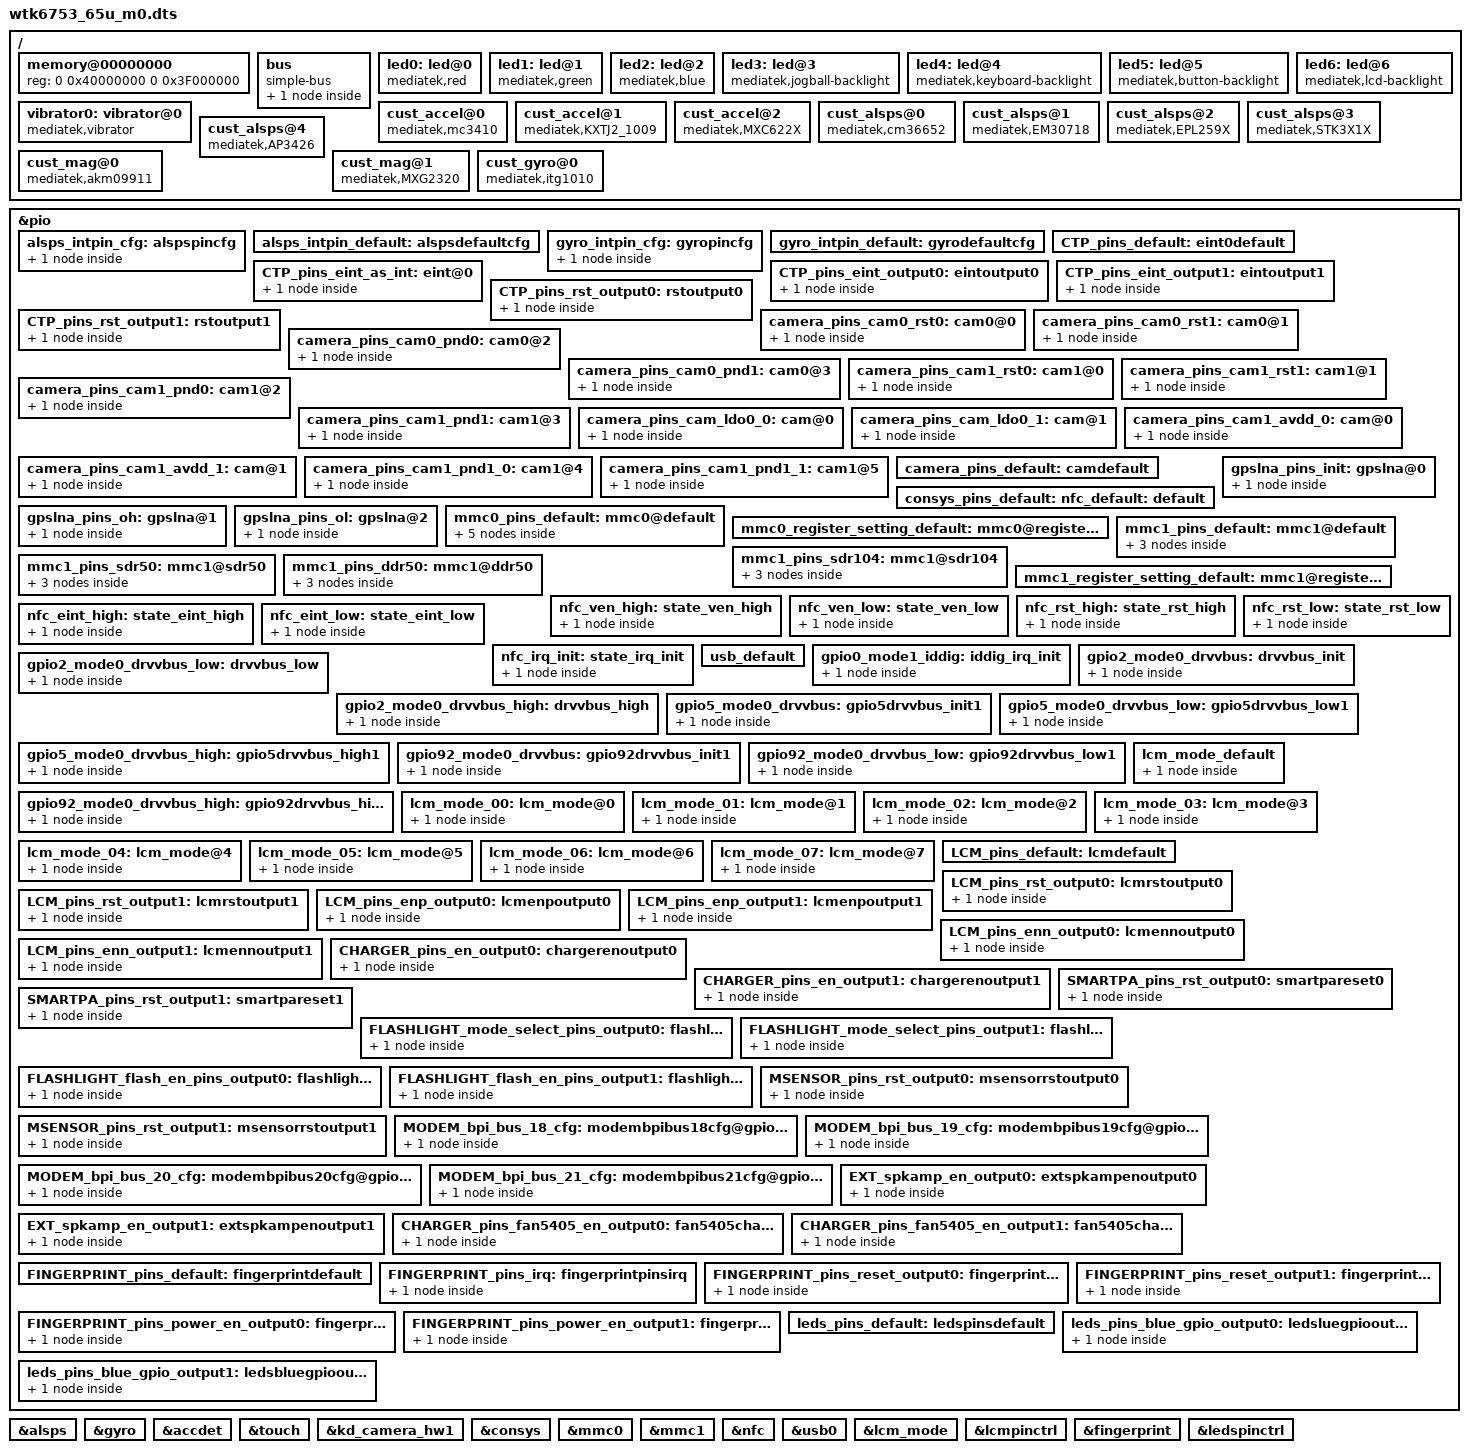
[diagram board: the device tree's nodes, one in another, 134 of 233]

/dts-v1/;

#include "mt6753.dtsi"
#include <dt-bindings/lcm/r63417_fhd_dsi_cmd_truly_nt50358.dtsi>

/ {
memory@00000000 {
		device_type = "memory";
		reg = <0 0x40000000 0 0x3F000000>;
	};

	bus {
		compatible = "simple-bus";
		#address-cells = <1>;
		#size-cells = <1>;
		ranges = <0 0 0 0xffffffff>;

		MTKFB@5e200000 {
			compatible = "mediatek,MTKFB";
			reg = <0x7F000000 0x1000000>;
		};

	};
	led0:led@0 {
		compatible = "mediatek,red";
		led_mode = <3>;
		data = <2>;
		pwm_config = <0 0 0 0 0>;
	};
	led1:led@1 {
		compatible = "mediatek,green";
		led_mode = <3>;
		data = <1>;
		pwm_config = <0 0 0 0 0>;
	};
	led2:led@2 {
		compatible = "mediatek,blue";
		led_mode = <2>;
		data = <1>;
		pwm_config = <0 0 0 0 0>;
	};
	led3:led@3 {
		compatible = "mediatek,jogball-backlight";
		led_mode = <0>;
		data = <1>;
		pwm_config = <0 0 0 0 0>;
	};
	led4:led@4 {
		compatible = "mediatek,keyboard-backlight";
		led_mode = <0>;
		data = <1>;
		pwm_config = <0 0 0 0 0>;
	};
	led5:led@5 {
		compatible = "mediatek,button-backlight";
		led_mode = <0>;
		data = <1>;
		pwm_config = <0 0 0 0 0>;
	};
	led6:led@6 {
		compatible = "mediatek,lcd-backlight";
		led_mode = <5>;
		data = <1>;
		pwm_config = <0 0 0 0 0>;
	};
	vibrator0:vibrator@0 {
		compatible = "mediatek,vibrator";
		vib_timer = <25>;
		vib_limit = <9>;
		vib_vol= <5>;
	};
 /* sensor standardization */
		cust_accel@0 {
		compatible = "mediatek,mc3410";
		i2c_num	= <2>;
		i2c_addr = <0x4c 0 0 0>;
		direction = <0>;
		power_id = <0xffff>;
		power_vol = <0>;
		firlen = <0>;
		is_batch_supported = <0>;
		};
		/*KXTJ2_1009*/
		cust_accel@1 {
		compatible				= "mediatek,KXTJ2_1009";
		i2c_num					= <2>;
		i2c_addr				= <0x0f 0 0 0>;
		direction				= <2>;
		power_id				= <0xffff>;
		power_vol				= <0>;
		firlen					= <0>;
		is_batch_supported			= <0>;
		};
		/*MXC622X*/
		cust_accel@2 {
		compatible				= "mediatek,MXC622X";
		i2c_num					= <2>;
		i2c_addr				= <0x15 0 0 0>;
		direction				= <0>;
		power_id				= <0xffff>;
		power_vol				= <0>;
		firlen					= <0>;
		is_batch_supported			= <0>;
		};	
		
		cust_alsps@0 {
		compatible = "mediatek,cm36652";
		i2c_num	= <2>;
		i2c_addr = <0x60 0 0 0>;
		polling_mode_ps = <0>;
		polling_mode_als = <1>;
		power_id = <0xffff>;
		power_vol = <0>;
		als_level = <5 109 213 711 1143 2630 6803 6909 10736 19968 24783 29231 42000 51141 51141 51141>;
		als_value = <0 67 203 501 1005 2005 3209 5002 8006 10010 12000 16010 20000 20000 20000 20000>;
		ps_threshold_high		=  <32>;
		ps_threshold_low		=  <22>;
		is_batch_supported_ps	= <0>;
		is_batch_supported_als	= <0>;
		};
		cust_alsps@1 {
		compatible				= "mediatek,EM30718";
		i2c_num					= <2>;
		i2c_addr				= <0x24 0 0 0>;
		polling_mode_ps			= <1>;
		polling_mode_als		= <1>;
		power_id				= <0xffff>;
		power_vol				= <0>;
		/* Total has 15 level*/
		als_level	= <15 40 60 90 112 132 205 273 500 845 1136 1545 2364 4655 4095>;
		/*  Total has 16 range*/
		als_value	= <0 50 100 150 300 600 800 1000 1550 1930 2250 2700 3600 5120 7680 10240>;
		ps_threshold_high		=  <80>;
		ps_threshold_low		=  <60>;
		is_batch_supported_ps	= <0>;
		is_batch_supported_als	= <0>;
		};
		cust_alsps@2 {
		compatible				= "mediatek,EPL259X";
		i2c_num					= <2>;
		i2c_addr				= <0x49 0 0 0>;
		polling_mode_ps			= <1>;
		polling_mode_als		= <1>;
		power_id				= <0xffff>;
		power_vol				= <0>;
		/* Total has 15 level*/
		als_level	= <20 45 70 90 150 300 500 700 1150 2250 4500 8000 15000 30000 50000>;
		/*  Total has 16 range*/
		als_value	= <10 30 60 80 100 200 400 600 800 1500 3000 6000 10000 20000 40000 60000>;
		ps_threshold_high		=  <800>;
		ps_threshold_low		=  <500>;
		is_batch_supported_ps	= <0>;
		is_batch_supported_als	= <0>;
		};		
		cust_alsps@3 {
		compatible				= "mediatek,STK3X1X";
		i2c_num					= <2>;
		i2c_addr				= <0x48 0 0 0>;
		polling_mode_ps			= <1>;
		polling_mode_als		= <1>;
		power_id				= <0xffff>;
		power_vol				= <0>;
		/* Total has 15 level*/
		als_level	= <5  9 36 59 82 132 205 273 500 845 1136 1545 2364 4655 6982>;
		/*  Total has 16 range*/
		als_value	= <0 10 40 65 90 145 225 300 550 930 1250 1700 2600 5120 7680 10240>;
		ps_threshold_high		=  <600>;
		ps_threshold_low		=  <600>;
		is_batch_supported_ps	= <0>;
		is_batch_supported_als	= <0>;
		};
		cust_alsps@4 {
                compatible                              = "mediatek,AP3426";
                i2c_num                                 = <2>;
                i2c_addr                                = <0x1e 0 0 0>;
                polling_mode_ps                 = <1>;
                polling_mode_als                = <1>;
                power_id                                = <0xffff>;
                power_vol                               = <0>;
                /* Total has 15 level*/
                /*als_level     = <0 125 319 525 1091 2480 3058 5115 8589 10769 12857 17807 22091 65535 65535>;*/
                als_level       = <0 1 4 7 15 15 100 1000 2000 3000 6000 10000 14000 18000 20000>;
                /*  Total has 16 range*/
                /*als_value     = <0 133 303 504 1002 2003 3006 5003 8002 10000 12000 16000 20000 20000 20000 20000>;*/
                als_value       = <40 40 90 90 160 160 225 320 640 1280 1280 2600 2600 2600 10240 10240>;
                ps_threshold_high               =  <150>;
                ps_threshold_low                =  <100>;
                is_batch_supported_ps   = <0>;
                is_batch_supported_als  = <0>;
                }; 
		cust_mag@0 {
		compatible				= "mediatek,akm09911";
		i2c_num					= <2>;
		i2c_addr				= <0x0D 0 0 0>;
		direction				= <1>;
		power_id				= <0xffff>;
		power_vol				= <0>;
		is_batch_supported			= <0>;
		};
		cust_mag@1 {
		compatible                              = "mediatek,MXG2320";
		i2c_num                                 = <2>;
		i2c_addr                                = <0x0D 0 0 0>;
		direction                               = <0>;
		power_id                                = <0xffff>;
		power_vol                               = <0>;
		is_batch_supported                      = <0>;
                };
		cust_gyro@0 {
		compatible				= "mediatek,itg1010";
		i2c_num					= <2>;
		i2c_addr				= <0x68 0 0 0>;
		direction				= <3>;
		power_id				= <0xffff>;
		power_vol				= <0>;
		firlen					= <0>;
		is_batch_supported			= <0>;
		};
};
/* sensor gpio standization */
&pio {
	alsps_intpin_cfg: alspspincfg {

	    pins_cmd_dat {
			pins = <PINMUX_GPIO65__FUNC_GPIO65>;
			slew-rate = <0>;
			bias-pull-up = <00>;
		};
	};

	alsps_intpin_default: alspsdefaultcfg {

	};

	gyro_intpin_cfg: gyropincfg {

	    pins_cmd_dat {
			pins = <PINMUX_GPIO67__FUNC_GPIO67>;
			slew-rate = <0>;
			bias-pull-down = <00>;
		};
	};

	gyro_intpin_default: gyrodefaultcfg {

	};
};
&alsps {
	pinctrl-names = "pin_default", "pin_cfg";
	pinctrl-0 = <&alsps_intpin_default>;
	pinctrl-1 = <&alsps_intpin_cfg>;
	status = "okay";

};

&gyro {
	pinctrl-names = "pin_default", "pin_cfg";
	pinctrl-0 = <&gyro_intpin_default>;
	pinctrl-1 = <&gyro_intpin_cfg>;
	status = "okay";

};
/* sensor end */

&accdet {
		accdet-mic-vol = <7>;
		headset-mode-setting = <0x500 0x200 1 0x1F0 0x800 0x800 0x20>;
		accdet-plugout-debounce = <20>;
		/*1:ACC mode, 2:low cost without in bias, 6:low cost with in bias*/
		accdet-mic-mode = <6>;
		/*0--MD_MAX--UP_MAX--DW_MAX*/
		headset-three-key-threshold = <0 80 220 500>;
		/*0--MD_MAX--VOICE_MAX--UP_MAX--DW_MAX*/
		headset-four-key-threshold = <0 58 121 192 450>;
};
&touch {
	tpd-resolution = <1080 1920>;
	use-tpd-button = <1>;
	tpd-key-num = <3>;
	tpd-key-local= <139 172 158 0>;
	tpd-key-dim-local = <245 2000 100 40 540 2000 100 40 835 2000 100 40 0 0 0 0>;
	tpd-max-touch-num = <5>;
	tpd-filter-enable = <1>;
	tpd-filter-pixel-density = <124>;
	tpd-filter-custom-prameters = <0 0 0 0 0 0 0 0 0 0 0 0>;
	tpd-filter-custom-speed = <0 0 0>;
	pinctrl-names = "default", "state_eint_as_int", "state_eint_output0", "state_eint_output1",
		"state_rst_output0", "state_rst_output1";
	pinctrl-0 = <&CTP_pins_default>;
	pinctrl-1 = <&CTP_pins_eint_as_int>;
	pinctrl-2 = <&CTP_pins_eint_output0>;
	pinctrl-3 = <&CTP_pins_eint_output1>;
	pinctrl-4 = <&CTP_pins_rst_output0>;
	pinctrl-5 = <&CTP_pins_rst_output1>;
	status = "okay";
};
&pio {
	CTP_pins_default: eint0default {
	};
	CTP_pins_eint_as_int: eint@0 {
		pins_cmd_dat {
			pins = <PINMUX_GPIO10__FUNC_GPIO10>;
			slew-rate = <0>;
			bias-disable;
		};
	};
	CTP_pins_eint_output0: eintoutput0 {
		pins_cmd_dat {
			pins = <PINMUX_GPIO10__FUNC_GPIO10>;
			slew-rate = <1>;
			output-low;
		};
	};
	CTP_pins_eint_output1: eintoutput1 {
		pins_cmd_dat {
			pins = <PINMUX_GPIO10__FUNC_GPIO10>;
			slew-rate = <1>;
			output-high;
		};
	};
	CTP_pins_rst_output0: rstoutput0 {
		pins_cmd_dat {
			pins = <PINMUX_GPIO62__FUNC_GPIO62>;
			slew-rate = <1>;
			output-low;
		};
	};
	CTP_pins_rst_output1: rstoutput1 {
		pins_cmd_dat {
			pins = <PINMUX_GPIO62__FUNC_GPIO62>;
			slew-rate = <1>;
			output-high;
		};
	};
};
/* TOUCH end */
/* CAMERA GPIO standardization */
&pio {
	camera_pins_cam0_rst0: cam0@0 {
		pins_cmd_dat {
			pins = <PINMUX_GPIO44__FUNC_GPIO44>;/*GPIO_CAMERA_CMRST_PIN*/
			slew-rate = <1>; /*direction 0:in, 1:out*/
			output-low;/*direction out used only. output_low or high*/
		};
	};
	camera_pins_cam0_rst1: cam0@1 {
		pins_cmd_dat {
			pins = <PINMUX_GPIO44__FUNC_GPIO44>;/*GPIO_CAMERA_CMRST_PIN*/
			slew-rate = <1>;
			output-high;
		};
	};
	camera_pins_cam0_pnd0: cam0@2 {
		pins_cmd_dat {
			pins = <PINMUX_GPIO7__FUNC_GPIO7>;/*GPIO_CAMERA_CMPDN_PIN*/
			slew-rate = <1>;
			output-low;
		};
	};
	camera_pins_cam0_pnd1: cam0@3 {
		pins_cmd_dat {
			pins = <PINMUX_GPIO7__FUNC_GPIO7>;/*GPIO_CAMERA_CMPDN_PIN*/
			slew-rate = <1>;
			output-high;
		};
	};
	camera_pins_cam1_rst0: cam1@0 {
		pins_cmd_dat {
			pins = <PINMUX_GPIO43__FUNC_GPIO43>;/*GPIO_CAMERA_CMRST1_PIN*/
			slew-rate = <1>; /*direction 0:in, 1:out*/
			output-low;/*direction out used only. output_low or high*/
		};
	};
	camera_pins_cam1_rst1: cam1@1 {
		pins_cmd_dat {
			pins = <PINMUX_GPIO43__FUNC_GPIO43>;/*GPIO_CAMERA_CMRST1_PIN*/
			slew-rate = <1>;
			output-high;
		};
	};
	camera_pins_cam1_pnd0: cam1@2 {
		pins_cmd_dat {
			pins = <PINMUX_GPIO83__FUNC_GPIO83>;/*GPIO_CAMERA_CMPDN1_PIN*/
			slew-rate = <1>;
			output-low;
		};
	};
	camera_pins_cam1_pnd1: cam1@3 {
		pins_cmd_dat {
			pins = <PINMUX_GPIO83__FUNC_GPIO83>;/*GPIO_CAMERA_CMPDN1_PIN*/
			slew-rate = <1>;
			output-high;
		};
	};
	camera_pins_cam_ldo0_0: cam@0 {
		pins_cmd_dat {
			pins = <PINMUX_GPIO68__FUNC_GPIO68>;
			slew-rate = <1>;
			output-low;
		};
	};
	camera_pins_cam_ldo0_1: cam@1 {
		pins_cmd_dat {
			pins = <PINMUX_GPIO68__FUNC_GPIO68>;
			slew-rate = <1>;
			output-high;
		};
	};
	camera_pins_cam1_avdd_0: cam@0 {
		pins_cmd_dat {
			pins = <PINMUX_GPIO59__FUNC_GPIO59>;
			slew-rate = <1>;
			output-low;
		};
	};
	camera_pins_cam1_avdd_1: cam@1 {
		pins_cmd_dat {
			pins = <PINMUX_GPIO59__FUNC_GPIO59>;
			slew-rate = <1>;
			output-high;
		};
	};
	camera_pins_cam1_pnd1_0: cam1@4 {
		pins_cmd_dat {
			pins = <PINMUX_GPIO89__FUNC_GPIO89>;/*GPIO_CAMERA_CMPDN1_PIN*/
			slew-rate = <1>;
			output-low;
		};
	};
	camera_pins_cam1_pnd1_1: cam1@5 {
		pins_cmd_dat {
			pins = <PINMUX_GPIO89__FUNC_GPIO89>;/*GPIO_CAMERA_CMPDN1_PIN*/
			slew-rate = <1>;
			output-high;
		};
	};	
	camera_pins_default: camdefault {

	};
};

&kd_camera_hw1 {
	pinctrl-names = "default", "cam0_rst0", "cam0_rst1", "cam0_pnd0", "cam0_pnd1",
	"cam1_rst0", "cam1_rst1", "cam1_pnd0", "cam1_pnd1","cam_ldo0_0", "cam_ldo0_1",
	"cam1_avdd_0", "cam1_avdd_1","cam1_pnd1_0", "cam1_pnd1_1";
	pinctrl-0 = <&camera_pins_default>;
	pinctrl-1 = <&camera_pins_cam0_rst0>;
	pinctrl-2 = <&camera_pins_cam0_rst1>;
	pinctrl-3 = <&camera_pins_cam0_pnd0>;
	pinctrl-4 = <&camera_pins_cam0_pnd1>;
	pinctrl-5 = <&camera_pins_cam1_rst0>;
	pinctrl-6 = <&camera_pins_cam1_rst1>;
	pinctrl-7 = <&camera_pins_cam1_pnd0>;
	pinctrl-8 = <&camera_pins_cam1_pnd1>;
	pinctrl-9 = <&camera_pins_cam_ldo0_0>;
	pinctrl-10 = <&camera_pins_cam_ldo0_1>;
	pinctrl-11 = <&camera_pins_cam1_avdd_0>;
	pinctrl-12 = <&camera_pins_cam1_avdd_1>;
	pinctrl-13 = <&camera_pins_cam1_pnd1_0>;
	pinctrl-14 = <&camera_pins_cam1_pnd1_1>;
	status = "okay";

};
/* CAMERA GPIO end */

/* CONSYS GPIO standardization */
&pio {
	consys_pins_default: default {

	};

	gpslna_pins_init: gpslna@0 {

	    pins_cmd_dat {
			pins = <PINMUX_GPIO19__FUNC_GPIO19>;
			slew-rate = <0>;
			bias-disable;
			output-low;
		};
	};

	gpslna_pins_oh: gpslna@1 {

	    pins_cmd_dat {
			pins = <PINMUX_GPIO19__FUNC_GPIO19>;
			slew-rate = <1>;
			output-high;
		};
	};

	gpslna_pins_ol: gpslna@2 {

	    pins_cmd_dat {
			pins = <PINMUX_GPIO19__FUNC_GPIO19>;
			slew-rate = <1>;
			output-low;
		};
	};

};

&consys {
	pinctrl-names = "default", "gps_lna_state_init", "gps_lna_state_oh", "gps_lna_state_ol";
	pinctrl-0 = <&consys_pins_default>;
	pinctrl-1 = <&gpslna_pins_init>;
	pinctrl-2 = <&gpslna_pins_oh>;
	pinctrl-3 = <&gpslna_pins_ol>;
	status = "okay";

};
/* CONSYS end */
/* mmc start */
&mmc0 {
		clk_src = /bits/ 8 <MSDC50_CLKSRC_400MHZ>;
		bus-width = <8>;
		max-frequency = <200000000>;
		cap-mmc-highspeed;
		msdc-sys-suspend;
		mmc-ddr-1_8v;
		mmc-hs200-1_8v;
		mmc-hs400-1_8v;
		non-removable;
		pinctl = <&mmc0_pins_default>;
		register_setting = <&mmc0_register_setting_default>;
		host_function = /bits/ 8 <MSDC_EMMC>;
		bootable;
		status = "okay";
};

&mmc1 {
		clk_src = /bits/ 8 <MSDC30_CLKSRC_200MHZ>;
		bus-width = <4>;
		max-frequency = <200000000>;
		msdc-sys-suspend;
		cap-sd-highspeed;
		non-removable;
		sd-uhs-sdr12;
		sd-uhs-sdr25;
		sd-uhs-sdr50;
		sd-uhs-sdr104;
		sd-uhs-ddr50;
		pinctl = <&mmc1_pins_default>;
		pinctl_sdr104 = <&mmc1_pins_sdr104>;
		pinctl_sdr50 = <&mmc1_pins_sdr50>;
		pinctl_ddr50 = <&mmc1_pins_ddr50>;
		register_setting = <&mmc1_register_setting_default>;
		host_function = /bits/ 8 <MSDC_SD>;
		/*cd_level = /bits/ 8 <MSDC_CD_LOW>;*/
		/*cd-gpios = <&pio 5 0>;*/
		status = "okay";
};

&pio {
	mmc0_pins_default: mmc0@default {
			pins_cmd {
				drive-strength = /bits/ 8 <2>;
			};
			pins_dat {
				drive-strength = /bits/ 8 <2>;
			};
			pins_clk {
				drive-strength = /bits/ 8 <2>;
			};
			pins_rst {
				drive-strength = /bits/ 8 <2>;
			};
			pins_ds {
				drive-strength = /bits/ 8 <2>;
			};
	};

	mmc0_register_setting_default: mmc0@register_default {
		dat0rddly      = /bits/ 8 <0>;
		dat1rddly      = /bits/ 8 <0>;
		dat2rddly      = /bits/ 8 <0>;
		dat3rddly      = /bits/ 8 <0>;
		dat4rddly      = /bits/ 8 <0>;
		dat5rddly      = /bits/ 8 <0>;
		dat6rddly      = /bits/ 8 <0>;
		dat7rddly      = /bits/ 8 <0>;
		datwrddly      = /bits/ 8 <0>;
		cmdrrddly      = /bits/ 8 <0>;
		cmdrddly       = /bits/ 8 <0>;
		cmd_edge = /bits/ 8 <MSDC_SMPL_FALLING>;
		rdata_edge = /bits/ 8 <MSDC_SMPL_FALLING>;
		wdata_edge = /bits/ 8 <MSDC_SMPL_FALLING>;

		ett-hs200-cells = <12>;
		ett-hs200-default = <OFFSET_MSDC_PATCH_BIT0	MSDC_PB0_INT_DAT_LATCH_CK_SEL 0x0
			OFFSET_MSDC_PATCH_BIT0	MSDC_PB0_CKGEN_MSDC_DLY_SEL   0x0
			OFFSET_MSDC_PATCH_BIT1	MSDC_PB1_CMD_RSP_TA_CNTR      0x1
			OFFSET_MSDC_IOCON		MSDC_IOCON_RSPL               0x1
			OFFSET_MSDC_PAD_TUNE0	MSDC_PAD_TUNE0_CMDRDLY        0xf
			OFFSET_MSDC_PAD_TUNE0	MSDC_PAD_TUNE0_CMDRRDLY       0x0
			OFFSET_MSDC_PATCH_BIT1		MSDC_PB1_WRDAT_CRCS_TA_CNTR   0x1
			OFFSET_MSDC_PAD_TUNE0	MSDC_PAD_TUNE0_DATWRDLY       0xf
			OFFSET_MSDC_IOCON			MSDC_IOCON_W_D0SPL            0x1
			OFFSET_MSDC_DAT_RDDLY0		MSDC_DAT_RDDLY0_D0            0xf
			OFFSET_MSDC_PAD_TUNE0	MSDC_PAD_TUNE0_DATRRDLY       0x16
			OFFSET_MSDC_IOCON		MSDC_IOCON_R_D_SMPL           0x0>;

		ett-hs400-cells = <8>;
		ett-hs400-default = <OFFSET_MSDC_PATCH_BIT0	MSDC_PB0_INT_DAT_LATCH_CK_SEL	0x0
			OFFSET_MSDC_PATCH_BIT0		MSDC_PB0_CKGEN_MSDC_DLY_SEL		0x0
			OFFSET_EMMC50_PAD_DS_TUNE	MSDC_EMMC50_PAD_DS_TUNE_DLY1	0x2
			OFFSET_EMMC50_PAD_DS_TUNE	MSDC_EMMC50_PAD_DS_TUNE_DLY3	0xe
			OFFSET_MSDC_PATCH_BIT1			MSDC_PB1_CMD_RSP_TA_CNTR	0x1
			OFFSET_MSDC_IOCON		MSDC_IOCON_RSPL				0x0
			OFFSET_MSDC_PAD_TUNE0			MSDC_PAD_TUNE0_CMDRDLY		0xf
			OFFSET_MSDC_PAD_TUNE0		MSDC_PAD_TUNE0_CMDRRDLY		0xd>;
	};

	mmc1_pins_default: mmc1@default {
			pins_cmd {
				drive-strength = /bits/ 8 <3>;
			};
			pins_dat {
				drive-strength = /bits/ 8 <3>;
			};
			pins_clk {
				drive-strength = /bits/ 8 <3>;
			};
	};

	mmc1_pins_sdr104: mmc1@sdr104 {
			pins_cmd {
				drive-strength = /bits/ 8 <2>;
			};
			pins_dat {
				drive-strength = /bits/ 8 <2>;
			};
			pins_clk {
				drive-strength = /bits/ 8 <3>;
			};
	};

	mmc1_pins_sdr50: mmc1@sdr50 {
			pins_cmd {
				drive-strength = /bits/ 8 <2>;
			};
			pins_dat {
				drive-strength = /bits/ 8 <2>;
			};
			pins_clk {
				drive-strength = /bits/ 8 <3>;
			};
	};

	mmc1_pins_ddr50: mmc1@ddr50 {
			pins_cmd {
				drive-strength = /bits/ 8 <2>;
			};
			pins_dat {
				drive-strength = /bits/ 8 <2>;
			};
			pins_clk {
				drive-strength = /bits/ 8 <3>;
			};
	};

	mmc1_register_setting_default: mmc1@register_default {
				dat0rddly      = /bits/ 8 <0>;
				dat1rddly      = /bits/ 8 <0>;
				dat2rddly      = /bits/ 8 <0>;
				dat3rddly      = /bits/ 8 <0>;
				datwrddly      = /bits/ 8 <0>;
				cmdrrddly      = /bits/ 8 <0>;
				cmdrddly       = /bits/ 8 <0>;
				cmd_edge = /bits/ 8 <MSDC_SMPL_FALLING>;
				rdata_edge = /bits/ 8 <MSDC_SMPL_FALLING>;
				wdata_edge = /bits/ 8 <MSDC_SMPL_FALLING>;
	};
};
/* mmc end */

/* NFC GPIO standardization */
&pio {
	nfc_default: default {

	};

	nfc_ven_high: state_ven_high {
		pins_cmd_dat {
			pins = <PINMUX_GPIO4__FUNC_GPIO4>;
			slew-rate = <1>;
			output-high;
		};
	};

	nfc_ven_low: state_ven_low {
		pins_cmd_dat {
			pins = <PINMUX_GPIO4__FUNC_GPIO4>;
			slew-rate = <1>;
			output-low;
		};
	};

	nfc_rst_high: state_rst_high {
		pins_cmd_dat {
			pins = <PINMUX_GPIO3__FUNC_GPIO3>;
			slew-rate = <1>;
			output-high;
		};
	};

	nfc_rst_low: state_rst_low {
		pins_cmd_dat {
			pins = <PINMUX_GPIO3__FUNC_GPIO3>;
			slew-rate = <1>;
			output-low;
		};
	};

	nfc_eint_high: state_eint_high {
		pins_cmd_dat {
			pins = <PINMUX_GPIO1__FUNC_GPIO1>;
			slew-rate = <1>;
			output-high;
		};
	};

	nfc_eint_low: state_eint_low {
		pins_cmd_dat {
			pins = <PINMUX_GPIO1__FUNC_GPIO1>;
			slew-rate = <1>;
			output-low;
		};
	};

	nfc_irq_init: state_irq_init {
		pins_cmd_dat {
			pins = <PINMUX_GPIO2__FUNC_GPIO2>;
			slew-rate = <0>;
			bias-pull-down = <00>;
		};
	};
};

&nfc {
	pinctrl-names = "default", "ven_high", "ven_low", "rst_high", "rst_low", "eint_high", "eint_low", "irq_init";
	pinctrl-0 = <&nfc_default>;
	pinctrl-1 = <&nfc_ven_high>;
	pinctrl-2 = <&nfc_ven_low>;
	pinctrl-3 = <&nfc_rst_high>;
	pinctrl-4 = <&nfc_rst_low>;
	pinctrl-5 = <&nfc_eint_high>;
	pinctrl-6 = <&nfc_eint_low>;
	pinctrl-7 = <&nfc_irq_init>;
	status = "okay";
};
/* NFC end */

/* USB GPIO Kernal Standardization start */
&pio {
	usb_default: usb_default {
	};

	gpio0_mode1_iddig: iddig_irq_init {
		pins_cmd_dat {
			pins = <PINMUX_GPIO0__FUNC_IDDIG>;
			slew-rate = <0>;
			bias-pull-up = <00>;
		};
	};

	gpio2_mode0_drvvbus: drvvbus_init {
		pins_cmd_dat {
			pins = <PINMUX_GPIO2__FUNC_GPIO2>;
			slew-rate = <1>;
			bias-pull-up = <00>;
		};
	};

	gpio2_mode0_drvvbus_low: drvvbus_low {
		pins_cmd_dat {
			pins = <PINMUX_GPIO2__FUNC_GPIO2>;
			slew-rate = <1>;
			output-low;
			bias-pull-down = <00>;
		};
	};

	gpio2_mode0_drvvbus_high: drvvbus_high {
		pins_cmd_dat {
			pins = <PINMUX_GPIO2__FUNC_GPIO2>;
			slew-rate = <1>;
			output-high;
			bias-pull-down = <00>;
		};
	};
	
	gpio5_mode0_drvvbus: gpio5drvvbus_init1 {
		pins_cmd_dat {
			pins = <PINMUX_GPIO5__FUNC_GPIO5>;
			slew-rate = <1>;
			bias-pull-down = <00>;
		};
	};

	gpio5_mode0_drvvbus_low: gpio5drvvbus_low1 {
		pins_cmd_dat {
			pins = <PINMUX_GPIO5__FUNC_GPIO5>;
			slew-rate = <1>;
			output-low;
			bias-pull-down = <00>;
		};
	};

	gpio5_mode0_drvvbus_high: gpio5drvvbus_high1 {
		pins_cmd_dat {
			pins = <PINMUX_GPIO5__FUNC_GPIO5>;
			slew-rate = <1>;
			output-high;
			bias-pull-down = <00>;
		};
	};
	
	gpio92_mode0_drvvbus: gpio92drvvbus_init1 {
		pins_cmd_dat {
			pins = <PINMUX_GPIO92__FUNC_GPIO92>;
			slew-rate = <1>;
			bias-pull-down = <00>;
		};
	};

	gpio92_mode0_drvvbus_low: gpio92drvvbus_low1 {
		pins_cmd_dat {
			pins = <PINMUX_GPIO92__FUNC_GPIO92>;
			slew-rate = <1>;
			output-low;
			bias-pull-down = <00>;
		};
	};

	gpio92_mode0_drvvbus_high: gpio92drvvbus_high1 {
		pins_cmd_dat {
			pins = <PINMUX_GPIO92__FUNC_GPIO92>;
			slew-rate = <1>;
			output-high;
			bias-pull-down = <00>;
		};
	};	
};

&usb0 {
	iddig_gpio = <0 1>;
	pinctrl-names = "usb_default", "iddig_irq_init", "drvvbus_init", "drvvbus_low", "drvvbus_high", "gpio5_drvvbus_init", "gpio5_drvvbus_low", "gpio5_drvvbus_high","gpio92_drvvbus_init", "gpio92_drvvbus_low", "gpio92_drvvbus_high";
	pinctrl-0 = <&usb_default>;
	pinctrl-1 = <&gpio0_mode1_iddig>;
	pinctrl-2 = <&gpio2_mode0_drvvbus>;
	pinctrl-3 = <&gpio2_mode0_drvvbus_low>;
	pinctrl-4 = <&gpio2_mode0_drvvbus_high>;
	pinctrl-5 = <&gpio5_mode0_drvvbus>;
	pinctrl-6 = <&gpio5_mode0_drvvbus_low>;
	pinctrl-7 = <&gpio5_mode0_drvvbus_high>;
	pinctrl-8 = <&gpio92_mode0_drvvbus>;
	pinctrl-9 = <&gpio92_mode0_drvvbus_low>;
	pinctrl-10 = <&gpio92_mode0_drvvbus_high>;
	status = "okay";
};
/* USB GPIO Kernal Standardization end */

/* LCM GPIO Kernal Standardization start */
&pio {
	lcm_mode_default: lcm_mode_default {
		pins_cmd_dat {
			pins = <PINMUX_GPIO80__FUNC_GPIO80>;
		};
	};

	lcm_mode_00: lcm_mode@0 {
		pins_cmd_dat {
			pins = <PINMUX_GPIO80__FUNC_GPIO80>;
		};
	};

	lcm_mode_01: lcm_mode@1 {
		pins_cmd_dat {
			pins = <PINMUX_GPIO80__FUNC_I2S0_BCK>;
		};
	};

	lcm_mode_02: lcm_mode@2 {
		pins_cmd_dat {
			pins = <PINMUX_GPIO80__FUNC_PCM1_CLK_1>;
		};
	};

	lcm_mode_03: lcm_mode@3 {
		pins_cmd_dat {
			pins = <PINMUX_GPIO80__FUNC_I2S3_BCK>;
		};
	};

	lcm_mode_04: lcm_mode@4 {
		pins_cmd_dat {
			pins = <PINMUX_GPIO80__FUNC_I2S1_BCK>;
		};
	};

	lcm_mode_05: lcm_mode@5 {
		pins_cmd_dat {
			pins = <PINMUX_GPIO80__FUNC_PWM4>;
		};
	};

	lcm_mode_06: lcm_mode@6 {
		pins_cmd_dat {
			pins = <PINMUX_GPIO80__FUNC_I2S2_BCK>;
		};
	};

	lcm_mode_07: lcm_mode@7 {
		pins_cmd_dat {
			pins = <PINMUX_GPIO80__FUNC_DBG_MON_A28>;
		};
	};
};

&lcm_mode {
	pinctrl-names = "default", "lcm_mode_00", "lcm_mode_01", "lcm_mode_02", "lcm_mode_03", "lcm_mode_04",
	 "lcm_mode_05", "lcm_mode_06", "lcm_mode_07";
	pinctrl-0 = <&lcm_mode_default>;
	pinctrl-1 = <&lcm_mode_00>;
	pinctrl-2 = <&lcm_mode_01>;
	pinctrl-3 = <&lcm_mode_02>;
	pinctrl-4 = <&lcm_mode_03>;
	pinctrl-5 = <&lcm_mode_04>;
	pinctrl-6 = <&lcm_mode_05>;
	pinctrl-7 = <&lcm_mode_06>;
	pinctrl-8 = <&lcm_mode_07>;
	lcm_power_gpio = <&pio 80 0>;
	lcm_bl_gpio = <&pio 129 0>;
	status = "okay";
};
/* LCM GPIO Kernal Standardization end */
/*LY Project  Start added by xiehaifei*/
&lcmpinctrl {
    pinctrl-names = "default","state_lcm_rst_output0","state_lcm_rst_output1","state_lcm_enp_output0","state_lcm_enp_output1","state_lcm_enn_output0","state_lcm_enn_output1",
        "state_charger_en_output0","state_charger_en_output1","state_smartpa_reset_output0","state_smartpa_reset_output1", 
	"state_flashlight_mode_select_output0","state_flashlight_mode_select_output1","state_flashlight_flash_en_output0","state_flashlight_flash_en_output1","state_msensor_rst_output0","state_msensor_rst_output1",
	"state_modem_bpi_bus_19_cfg","state_modem_bpi_bus_20_cfg","state_modem_bpi_bus_21_cfg","state_ext_spkamp_en_output0","state_ext_spkamp_en_output1","state_modem_bpi_bus_18_cfg",
	"state_fan5405_charger_en_output0","state_fan5405_charger_en_output1";
    pinctrl-0 = <&LCM_pins_default>;
    pinctrl-1 = <&LCM_pins_rst_output0>;
    pinctrl-2 = <&LCM_pins_rst_output1>;
    pinctrl-3 = <&LCM_pins_enp_output0>;
    pinctrl-4 = <&LCM_pins_enp_output1>;
    pinctrl-5 = <&LCM_pins_enn_output0>;
    pinctrl-6 = <&LCM_pins_enn_output1>;
    pinctrl-7 = <&CHARGER_pins_en_output0>;
    pinctrl-8 = <&CHARGER_pins_en_output1>;
    pinctrl-9 = <&SMARTPA_pins_rst_output0>;
    pinctrl-10 = <&SMARTPA_pins_rst_output1>;
    pinctrl-11 = <&FLASHLIGHT_mode_select_pins_output0>;
    pinctrl-12 = <&FLASHLIGHT_mode_select_pins_output1>;
    pinctrl-13 = <&FLASHLIGHT_flash_en_pins_output0>;
    pinctrl-14 = <&FLASHLIGHT_flash_en_pins_output1>;
    pinctrl-15 = <&MSENSOR_pins_rst_output0>;
    pinctrl-16 = <&MSENSOR_pins_rst_output1>;
    pinctrl-17 = <&MODEM_bpi_bus_19_cfg>;
    pinctrl-18 = <&MODEM_bpi_bus_20_cfg>;
    pinctrl-19 = <&MODEM_bpi_bus_21_cfg>;
    pinctrl-20 = <&EXT_spkamp_en_output0>;
    pinctrl-21 = <&EXT_spkamp_en_output1>;
    pinctrl-22 = <&MODEM_bpi_bus_18_cfg>;
    pinctrl-23 = <&CHARGER_pins_fan5405_en_output0>;
    pinctrl-24 = <&CHARGER_pins_fan5405_en_output1>;
    status = "okay";
};
&pio {
    LCM_pins_default: lcmdefault {
	};
	LCM_pins_rst_output0: lcmrstoutput0 {
		pins_cmd_dat {
			pins = <PINMUX_GPIO146__FUNC_GPIO146>;
			slew-rate = <1>;
			output-low;
		};
	};
	LCM_pins_rst_output1: lcmrstoutput1 {
		pins_cmd_dat {
			pins = <PINMUX_GPIO146__FUNC_GPIO146>;
			slew-rate = <1>;
			output-high;
		};
	};
    LCM_pins_enp_output0: lcmenpoutput0 {
		pins_cmd_dat {
			pins = <PINMUX_GPIO82__FUNC_GPIO82>;
			slew-rate = <1>;
			output-low;
		};
	};
	LCM_pins_enp_output1: lcmenpoutput1 {
		pins_cmd_dat {
			pins = <PINMUX_GPIO82__FUNC_GPIO82>;
			slew-rate = <1>;
			output-high;
		};
	};
    LCM_pins_enn_output0: lcmennoutput0 {
		pins_cmd_dat {
			pins = <PINMUX_GPIO88__FUNC_GPIO88>;
			slew-rate = <1>;
			output-low;
		};
	};
    LCM_pins_enn_output1: lcmennoutput1 {
		pins_cmd_dat {
			pins = <PINMUX_GPIO88__FUNC_GPIO88>;
			slew-rate = <1>;
			output-high;
		};
	};
    CHARGER_pins_en_output0: chargerenoutput0 {
		pins_cmd_dat {
			pins = <PINMUX_GPIO92__FUNC_GPIO92>;
			slew-rate = <1>;
			output-low;
		};
	};
    CHARGER_pins_en_output1: chargerenoutput1 {
		pins_cmd_dat {
			pins = <PINMUX_GPIO92__FUNC_GPIO92>;
			slew-rate = <1>;
			output-high;
		};
	};
    SMARTPA_pins_rst_output0: smartpareset0 {
		pins_cmd_dat {
			pins = <PINMUX_GPIO87__FUNC_GPIO87>;
			slew-rate = <0>;
			output-low;
		};
	};
    SMARTPA_pins_rst_output1: smartpareset1 {
		pins_cmd_dat {
			pins = <PINMUX_GPIO87__FUNC_GPIO87>;
			slew-rate = <1>;
			output-high;
		};
	};
    FLASHLIGHT_mode_select_pins_output0: flashlightmodeselect0 {
		pins_cmd_dat {
			pins = <PINMUX_GPIO94__FUNC_GPIO94>;
			slew-rate = <1>;
			output-low;
		};
	};
    FLASHLIGHT_mode_select_pins_output1: flashlightmodeselect1 {
		pins_cmd_dat {
			pins = <PINMUX_GPIO94__FUNC_GPIO94>;
			slew-rate = <1>;
			output-high;
		};
	};
    FLASHLIGHT_flash_en_pins_output0: flashlightflashen0 {
		pins_cmd_dat {
			pins = <PINMUX_GPIO93__FUNC_GPIO93>;
			slew-rate = <1>;
			output-low;
		};
	};
    FLASHLIGHT_flash_en_pins_output1: flashlightflashen1 {
		pins_cmd_dat {
			pins = <PINMUX_GPIO93__FUNC_GPIO93>;
			slew-rate = <1>;
			output-high;
		};
	};
    MSENSOR_pins_rst_output0: msensorrstoutput0 {
		pins_cmd_dat {
			pins = <PINMUX_GPIO61__FUNC_GPIO61>;
			slew-rate = <1>;
			output-low;
		};
	};
    MSENSOR_pins_rst_output1: msensorrstoutput1 {
		pins_cmd_dat {
			pins = <PINMUX_GPIO61__FUNC_GPIO61>;
			slew-rate = <1>;
			output-high;
		};
	};	
    MODEM_bpi_bus_18_cfg: modembpibus18cfg@gpio100 {
               pins_cmd_dat {
			pins = <PINMUX_GPIO100__FUNC_BPI_BUS18>;
		};
	};			
    MODEM_bpi_bus_19_cfg: modembpibus19cfg@gpio101 {
               pins_cmd_dat {
			pins = <PINMUX_GPIO101__FUNC_BPI_BUS19>;
		};
	};
    MODEM_bpi_bus_20_cfg: modembpibus20cfg@gpio102 {
        pins_cmd_dat {
			pins = <PINMUX_GPIO102__FUNC_BPI_BUS20>;
		};
	};
    MODEM_bpi_bus_21_cfg: modembpibus21cfg@gpio124 {
        pins_cmd_dat {
			pins = <PINMUX_GPIO124__FUNC_BPI_BUS21>;
		};
	};
   EXT_spkamp_en_output0: extspkampenoutput0 {
		pins_cmd_dat {
			pins = <PINMUX_GPIO87__FUNC_GPIO87>;
			slew-rate = <0>;
			output-low;
		};
	};
    EXT_spkamp_en_output1: extspkampenoutput1 {
		pins_cmd_dat {
			pins = <PINMUX_GPIO87__FUNC_GPIO87>;
			slew-rate = <1>;
			output-high;
		};
	};
    CHARGER_pins_fan5405_en_output0: fan5405chargerenoutput0 {
		pins_cmd_dat {
			pins = <PINMUX_GPIO91__FUNC_GPIO91>;
			slew-rate = <1>;
			output-low;
		};
	};
    CHARGER_pins_fan5405_en_output1: fan5405chargerenoutput1 {
		pins_cmd_dat {
			pins = <PINMUX_GPIO91__FUNC_GPIO91>;
			slew-rate = <1>;
			output-high;
		};
	};		
};
/*FINGERPRINT added by xiehaifei 20160226*/
&fingerprint {
	pinctrl-names = "default", "state_fingerprint_irq", "state_fingerprint_reset_output0", "state_fingerprint_reset_output1", "state_fingerprint_power_en_output0", "state_fingerprint_power_en_output1";
	pinctrl-0 = <&FINGERPRINT_pins_default>;
   	pinctrl-1 = <&FINGERPRINT_pins_irq>;
	pinctrl-2 = <&FINGERPRINT_pins_reset_output0>;
    	pinctrl-3 = <&FINGERPRINT_pins_reset_output1>;
    	pinctrl-4 = <&FINGERPRINT_pins_power_en_output0>;
    	pinctrl-5 = <&FINGERPRINT_pins_power_en_output1>;
	status = "okay";
};
&pio {
	FINGERPRINT_pins_default: fingerprintdefault {
	};
	FINGERPRINT_pins_irq: fingerprintpinsirq {
		pins_cmd_dat {
			pins = <PINMUX_GPIO9__FUNC_GPIO9>;
			slew-rate = <0>;
			bias-disable;
		};
	};
	FINGERPRINT_pins_reset_output0: fingerprintpinsresetout0 {
		pins_cmd_dat {
			pins = <PINMUX_GPIO127__FUNC_GPIO127>;
			slew-rate = <1>;
			output-low;
		};
	};
	FINGERPRINT_pins_reset_output1: fingerprintpinsresetout1 {
		pins_cmd_dat {
			pins = <PINMUX_GPIO127__FUNC_GPIO127>;
			slew-rate = <1>;
			output-high;
		};
	};
	FINGERPRINT_pins_power_en_output0: fingerprintpinspowerenout0 {
		pins_cmd_dat {
			pins = <PINMUX_GPIO89__FUNC_GPIO89>;
			slew-rate = <1>;
			output-low;
		};
	};
	FINGERPRINT_pins_power_en_output1: fingerprintpinspowerenout1 {
		pins_cmd_dat {
			pins = <PINMUX_GPIO89__FUNC_GPIO89>;
			slew-rate = <1>;
			output-high;
		};
	};
};
/*FINGERPRINT END*/

/*THREE COLOR LEDS :GPIO CONFIG*/
/*add leds gpio pinctrl start*/
&pio {
       leds_pins_default: ledspinsdefault {
       };
       leds_pins_blue_gpio_output0: ledsluegpiooutput0 {
               pins_cmd_dat {
                       pins = <PINMUX_GPIO86__FUNC_GPIO86>;
                       slew-rate = <1>;
                       output-low;
               };
       };
       leds_pins_blue_gpio_output1: ledsbluegpiooutput1 {
               pins_cmd_dat {
                       pins = <PINMUX_GPIO86__FUNC_GPIO86>;
                       slew-rate = <1>;
                       output-high;
               };
       };
};
&ledspinctrl {
       pinctrl-names = "default", "state_leds_blue_gpio_output0","state_leds_blue_gpio_output1";
       pinctrl-0 = <&leds_pins_default>;
       pinctrl-1 = <&leds_pins_blue_gpio_output0>;
       pinctrl-2 = <&leds_pins_blue_gpio_output1>;
       status = "okay";
};
/*led gpio send*/
/*LY Project ended by xiehaifei*/

